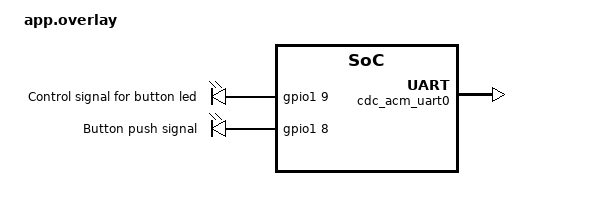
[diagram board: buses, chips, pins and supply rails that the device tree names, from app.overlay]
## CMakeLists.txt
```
#
# Copyright (c) 2024 Nordic Semiconductor
#
# SPDX-License-Identifier: LicenseRef-Nordic-5-Clause
#

cmake_minimum_required(VERSION 3.20.0)
find_package(Zephyr REQUIRED HINTS $ENV{ZEPHYR_BASE})
project(iso_time_sync)

target_include_directories(app PRIVATE include)
target_sources(app PRIVATE src/main.c src/timed_led_toggle.c src/uart_console.c src/buzzer.c src/buzzer_control.c src/param_stack.c)

if (CONFIG_BT_CENTRAL)
    target_sources(app PRIVATE src/central.c)
endif()

if (CONFIG_BT_PERIPHERAL)
    target_sources(app PRIVATE src/peripheral.c)
endif()

if (CONFIG_SOC_COMPATIBLE_NRF52X)
    target_sources(app PRIVATE src/controller_time_nrf52.c)
elseif (CONFIG_SOC_COMPATIBLE_NRF5340_CPUAPP)
    target_sources(app PRIVATE src/controller_time_nrf53_app.c)
elseif (CONFIG_SOC_SERIES_NRF54LX)
    target_sources(app PRIVATE src/controller_time_nrf54l.c)
else()
    MESSAGE(FATAL_ERROR "Unsupported series")
endif()
```

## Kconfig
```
source "Kconfig.zephyr"

config BUZZER_ROLE_MODE_CONTROLLER
	bool "Act as the buzzer controller"
```

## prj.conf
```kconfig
#
# Copyright (c) 2024 Nordic Semiconductor
#
# SPDX-License-Identifier: LicenseRef-Nordic-5-Clause
#

CONFIG_NCS_SAMPLES_DEFAULTS=y

CONFIG_BT_DEVICE_NAME="Buzzer"
CONFIG_BT=y
CONFIG_BT_PERIPHERAL=y
CONFIG_BT_CENTRAL=y
CONFIG_BT_MAX_CONN=5
CONFIG_BT_CTLR_SDC_PERIPHERAL_COUNT=1
CONFIG_BT_CTLR_TX_PWR_PLUS_8=y

CONFIG_BT_CONN_TX_MAX=250
CONFIG_BT_L2CAP_TX_BUF_COUNT=250
CONFIG_BT_BUF_ACL_TX_COUNT=250

CONFIG_BT_GATT_CLIENT=y

CONFIG_CONSOLE=y
CONFIG_CONSOLE_SUBSYS=y
CONFIG_CONSOLE_HANDLER=y
CONFIG_CONSOLE_GETCHAR=y
CONFIG_UART_INTERRUPT_DRIVEN=y

CONFIG_BT_CTLR_SDC_CONN_ANCHOR_POINT_REPORT=y
CONFIG_BT_HCI_VS_EVT_USER=y

CONFIG_BUILD_OUTPUT_UF2=y
CONFIG_ROM_START_OFFSET=0x1000

CONFIG_USB_DEVICE_STACK=y
CONFIG_USB_DEVICE_PRODUCT="Zephyr CDC ACM sample"
CONFIG_USB_DEVICE_PID=0x0001

CONFIG_BUZZER_ROLE_MODE_CONTROLLER=y
```

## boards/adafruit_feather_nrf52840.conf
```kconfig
#
# Copyright (c) 2024 Nordic Semiconductor
#
# SPDX-License-Identifier: LicenseRef-Nordic-5-Clause
#

CONFIG_NRFX_TIMER1=y
CONFIG_NRFX_RTC2=y
CONFIG_NRFX_GPPI=y
CONFIG_NRFX_EGU0=y
```

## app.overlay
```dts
/*
 * Copyright (c) 2021 Nordic Semiconductor ASA
 *
 * SPDX-License-Identifier: Apache-2.0
 */
&zephyr_udc0 {
    cdc_acm_uart0: cdc_acm_uart0 {
    	compatible = "zephyr,cdc-acm-uart";
        label = "CDC_ACM_0";
    };
};

/ {
    leds {
        led_drive: led_drive0 {
            gpios = <&gpio1 9 0>;
            label = "Control signal for button led";
        };
        push_button: push_button0 {
            gpios = <&gpio1 8 0>;
            label = "Button push signal";
        };   
    };
};
```

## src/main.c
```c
/*
 * Copyright (c) 2024 Nordic Semiconductor ASA
 *
 * SPDX-License-Identifier: LicenseRef-Nordic-5-Clause
 */

#include <zephyr/kernel.h>
#include <zephyr/console/console.h>
#include "conn_time_sync.h"
#include <zephyr/usb/usb_device.h>
#include <zephyr/drivers/uart.h>
#include "uart_console.h"

int main(void)
{
	console_init();
	
#ifdef CONFIG_BUZZER_ROLE_MODE_CONTROLLER
	uart_console_printf("Configured as buzzer controller\n");
	central_start();
#else
	uart_console_printf("Configured as buzzer\n");
	peripheral_start();
#endif
}
```

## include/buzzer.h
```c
#ifndef BUZZER_H
#define BUZZER_H
#include <stdint.h>
#include <zephyr/bluetooth/gatt.h>

ssize_t buzzer_arm_recieved(struct bt_conn *conn,
    const struct bt_gatt_attr *attr,
    const void *buf, uint16_t len,
    uint16_t offset, uint8_t flags);
ssize_t buzzer_light_recieved(struct bt_conn *conn,
        const struct bt_gatt_attr *attr,
        const void *buf, uint16_t len,
        uint16_t offset, uint8_t flags);
void buzzer_device_init(void);
void pressed_ccc_cfg_changed(const struct bt_gatt_attr *attr,
	uint16_t value);
void buzzer_device_reset(void);
void buzzer_update_offset(uint64_t central_timestamp, uint64_t peripheral_timestamp);
void buzzer_set_arm_flag(void);

#endif // BUZZER_H
```

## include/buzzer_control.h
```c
#ifndef BUZZER_CONTROL_H
#define BUZZER_CONTROL_H
#include <stdint.h>
#include <zephyr/bluetooth/conn.h>

void buzzer_controller_init(void);
int get_buzzer_chars(struct bt_conn *conn, uint16_t *timed_handle);

void controller_arm(void);
void controller_reset(void);

#endif // BUZZER_CONTROL_H
```

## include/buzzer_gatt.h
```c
#ifndef BUZZER_GATT_H
#define BUZZER_GATT_H

#include <zephyr/bluetooth/gatt.h>

// Define the Buzzer service
#define BT_UUID_BUZZER_SERVICE_VAL \
	BT_UUID_128_ENCODE(0xB0B10002, 0x7009, 0x4BEE, 0xA6F8, 0xE1DC3FF02B92)
#define BT_UUID_BUZZER_SERVICE \
	BT_UUID_DECLARE_128(BT_UUID_BUZZER_SERVICE_VAL)

// Buzzer ARM Characteristic
#define BT_UUID_BUZZER_ARM_CHAR_VAL \
	BT_UUID_128_ENCODE(0xB0B10003, 0x7009, 0x4BEE, 0xA6F8, 0xE1DC3FF02B92)
#define BT_UUID_BUZZER_ARM_CHAR \
	BT_UUID_DECLARE_128(BT_UUID_BUZZER_ARM_CHAR_VAL)	

// Buzzer Pressed Characteristic
#define BT_UUID_BUZZER_PRESSED_CHAR_VAL \
	BT_UUID_128_ENCODE(0xB0B10004, 0x7009, 0x4BEE, 0xA6F8, 0xE1DC3FF02B92)
#define BT_UUID_BUZZER_PRESSED_CHAR \
	BT_UUID_DECLARE_128(BT_UUID_BUZZER_PRESSED_CHAR_VAL)	

// Buzzer Light Characteristic
#define BT_UUID_BUZZER_LIGHT_CHAR_VAL \
	BT_UUID_128_ENCODE(0xB0B10005, 0x7009, 0x4BEE, 0xA6F8, 0xE1DC3FF02B92)
#define BT_UUID_BUZZER_LIGHT_CHAR \
	BT_UUID_DECLARE_128(BT_UUID_BUZZER_LIGHT_CHAR_VAL)	

#endif // BUZZER_GATT_H
```

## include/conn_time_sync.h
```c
/*
 * Copyright (c) 2024 Nordic Semiconductor ASA
 *
 * SPDX-License-Identifier: LicenseRef-Nordic-5-Clause
 */

#ifndef CONN_TIME_SYNC_H__
#define CONN_TIME_SYNC_H__

/**
 * @file
 * @defgroup conn_time_sync Definitions for the connection time sync sample.
 * @{
 * @brief Definitions for the connection time sync sample.
 *
 * This file contains common definitions and API declarations
 * used by the sample.
 */

#include <stdint.h>
#include <stdbool.h>
#include <zephyr/kernel.h>

/** @brief  Timed action service UUID */
#define BT_UUID_TIMED_ACTION_SERVICE_VAL \
	BT_UUID_128_ENCODE(0xA88278D0, 0x7009, 0x4BEE, 0xA6F8, 0xE1DC3FF02B92)
#define BT_UUID_TIMED_ACTION_SERVICE \
	BT_UUID_DECLARE_128(BT_UUID_TIMED_ACTION_SERVICE_VAL)

/** @brief Timed action characteristic UUID */
#define BT_UUID_TIMED_ACTION_CHAR_VAL \
	BT_UUID_128_ENCODE(0xA88278D1, 0x7009, 0x4BEE, 0xA6F8, 0xE1DC3FF02B92)
#define BT_UUID_TIMED_ACTION_CHAR \
	BT_UUID_DECLARE_128(BT_UUID_TIMED_ACTION_CHAR_VAL)

/** @brief Start central demo. */
void central_start(void);

/** @brief Start peripheral demo. */
void peripheral_start(void);

/** @brief The timed action message
 *
 * The timed action message represents the information
 * sent from the central to the peripheral to allow time synchronization.
 * The anchor point information is the common time reference between
 * the central and peripheral.
 *
 * This samples transmits the anchor point time and trigger time
 * in a single packet. Other applications may consider sending those
 * separately.
 */
struct timed_action {
	uint64_t anchor_point_us_central_clock;
	uint16_t anchor_point_event_counter;
} __packed;

// static inline void timed_action_print(struct timed_action *action)
// {
// 	uart_printf("c_anchor point (time=%llu, counter=%u), c_trigger_time %llu, value %d\n",
// 		action->anchor_point_us_central_clock,
// 		action->anchor_point_event_counter,
// 		action->trigger_time_us_central_clock,
// 		action->led_value);
// }

/** @brief Obtain the current Bluetooth controller time.
 *
 * The timestamps are based upon this clock.
 *
 * @return The current controller time.
 */
uint64_t controller_time_us_get(void);

/** @brief Set the controller to trigger a PPI event at the given timestamp.
 *
 * @param timestamp_us The timestamp where it will trigger.
 */
void controller_time_trigger_set(uint64_t timestamp_us);

/** @brief Get the address of the event that will trigger.
 *
 * @return The address of the event that will trigger.
 */
uint32_t controller_time_trigger_event_addr_get(void);

/** @brief Initialize the module handling timed toggling of an LED.
 *
 * @return 0 on success, failure otherwise.
 */
int timed_led_toggle_init(void);

/** @brief Toggle the LED using the given value at the given timestamp.
 *
 * @param value The LED value.
 * @param timestamp_us The time when the LED will be set, in microseconds.
 *                     The time is specified in controller clock units.
 */
void timed_led_toggle_trigger_at(uint8_t value, uint32_t timestamp_us);

#endif

/**
 * @}
 */
```

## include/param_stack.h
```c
#ifndef PARAM_STACK_H
#define PARAM_STACK_H
#include <zephyr/bluetooth/gatt.h>
int param_stack_get_write(struct bt_gatt_write_params **data);
int param_stack_get_read(struct bt_gatt_read_params **data);
int param_stack_free_write(struct bt_gatt_write_params *data);
int param_stack_free_read(struct bt_gatt_read_params *data);
#endif
```

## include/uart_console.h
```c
#ifndef UART_CONSOLE_H__
#define UART_CONSOLE_H__
void uart_console_printf(char *fmt, ...);
void uart_console_command_loop(void);
#endif
```

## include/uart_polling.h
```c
#ifndef UART_POLLING_H__
#define UART_POLLING_H__
int uart_poll_init(void);
void uart_poll_print(char *message);
void uart_printf(char *fmt, ...);
int uart_get_char(char *character);
#endif
```

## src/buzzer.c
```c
#include <zephyr/kernel.h>
#include <zephyr/bluetooth/gatt.h>
#include <zephyr/sys/atomic.h>
#include <zephyr/drivers/gpio.h>
#include "uart_console.h"
#include "conn_time_sync.h"
#include "param_stack.h"
#include "buzzer_gatt.h"

#define BUZZER_LOCKOUT 2000
#define BUZZER_LED_FLASH_DELAY_MS 200

// Data structure definitions
// Buzzer state struct
struct buzzer_params {
	uint64_t buzzer_pushed_timestamp; 
	uint64_t armed_timestamp;
	atomic_t lock;
	atomic_t armed;
	uint8_t lights;
};

struct buzzer_sync {
    int64_t offset_to_central;
    atomic_t offset_valid;
};

// Consts
static const struct gpio_dt_spec input_button = GPIO_DT_SPEC_GET(DT_NODELABEL(push_button), gpios);
static const struct gpio_dt_spec led_drive = GPIO_DT_SPEC_GET(DT_NODELABEL(led_drive), gpios);

// Function Declarations
void buzzer_led_init(void);
void buzzer_led_on(void);
void buzzer_led_off(void);
void buzzer_led_start_flash(void);

// Callback data for gpio
static struct gpio_callback pin_cb_data;

// Device state
static struct buzzer_params buzzer_state;
static atomic_t indicate_flag;
static struct bt_gatt_indicate_params ind_params;
static struct buzzer_sync buzzer_timing;
static int led_state = 0;

// Function Declarations
static void on_indicate_buzzer_time(struct k_work *work);

void buzzer_update_offset(uint64_t central_timestamp, uint64_t peripheral_timestamp)
{
    buzzer_timing.offset_to_central = central_timestamp - peripheral_timestamp;
    atomic_set_bit(&buzzer_timing.offset_valid, 0);
}

static void on_reenable_buzzer(struct k_work *work)
{
	gpio_pin_interrupt_configure_dt(&input_button, GPIO_INT_EDGE_TO_ACTIVE);
}
K_WORK_DELAYABLE_DEFINE(buzzer_reenable, on_reenable_buzzer);


K_WORK_DEFINE(indicate_buzzer_time, on_indicate_buzzer_time);

// Buzzer button ISR
static void pin_isr_buzzer(const struct device *dev, struct gpio_callback *cb, uint32_t pins)
{
	// Check if buzzer is not armed
	if(!atomic_test_bit(&buzzer_state.armed, 0)){
		// Disable buzzer for BUZZER_LOCKOUT
		uart_console_printf("Buzzer Locked\n");
		gpio_pin_interrupt_configure_dt(&input_button, GPIO_INT_DISABLE);
		k_work_schedule(&buzzer_reenable, K_MSEC(BUZZER_LOCKOUT));
	}
	// Buzzer is armed, check if we already have a valid buzz time and valid offset
	else if(!buzzer_state.buzzer_pushed_timestamp && atomic_test_bit(&buzzer_timing.offset_valid, 0)){
		// Set the buzzer time
		buzzer_state.buzzer_pushed_timestamp = controller_time_us_get() + buzzer_timing.offset_to_central;
		uart_console_printf("Buzzed in @ %llu central\n", buzzer_state.buzzer_pushed_timestamp);
		k_work_submit(&indicate_buzzer_time);
	}
}


static void gpio_input_config(void)
{
	gpio_pin_configure_dt(&input_button, GPIO_INPUT | GPIO_PULL_UP);
	gpio_pin_interrupt_configure_dt(&input_button, GPIO_INT_EDGE_TO_ACTIVE);
	gpio_init_callback(&pin_cb_data, pin_isr_buzzer, BIT(input_button.pin));
	gpio_add_callback(input_button.port, &pin_cb_data);
}

void buzzer_device_init(void)
{
    gpio_input_config();
	buzzer_led_init();
}

void buzzer_device_reset(void)
{
    buzzer_state.buzzer_pushed_timestamp = 0;
    buzzer_state.armed_timestamp = 0;
    buzzer_state.lights = 0;
    atomic_clear_bit(&buzzer_state.armed, 0);
    atomic_clear_bit(&buzzer_state.lock, 0);
    atomic_clear_bit(&indicate_flag, 0);

    buzzer_timing.offset_to_central = 0;
    atomic_clear_bit(&buzzer_timing.offset_valid, 0);

	buzzer_led_off();
}


void pressed_ccc_cfg_changed(const struct bt_gatt_attr *attr,
	uint16_t value)
{
	if(value == BT_GATT_CCC_INDICATE){
		atomic_set_bit(&indicate_flag, 0);
		uart_console_printf("Client Subscribed\n");
	}else{
		atomic_clear_bit(&indicate_flag, 0);
		uart_console_printf("Client Unsubscribed\n");
	}
}


static void on_indicate_buzzer_time(struct k_work *work)
{
	// Check to see if we are still armed and indications are enabled
	if(atomic_test_bit(&buzzer_state.armed, 0) && atomic_test_bit(&indicate_flag, 0)){
		uart_console_printf("Indicate\n");
		ind_params.uuid = BT_UUID_BUZZER_PRESSED_CHAR;
		ind_params.func = NULL;
		ind_params.destroy = NULL;
		ind_params.data = &buzzer_state.buzzer_pushed_timestamp ;
		ind_params.len = sizeof(buzzer_state.buzzer_pushed_timestamp );
		bt_gatt_indicate(NULL, &ind_params);
	}
}
// Callback for the buzzer arming
ssize_t buzzer_arm_recieved(struct bt_conn *conn,
    const struct bt_gatt_attr *attr,
    const void *buf, uint16_t len,
    uint16_t offset, uint8_t flags)
{
    if (len != sizeof(buzzer_state.armed_timestamp) || offset != 0) {
        return BT_GATT_ERR(BT_ATT_ERR_INVALID_ATTRIBUTE_LEN);
    }

    // Obtain a lock for the buzzer struct
    if(atomic_test_and_set_bit(&buzzer_state.lock, 0)){
    uart_console_printf("ERROR ARM: Already Locked\n");
        return 0;
    }
    memcpy(&buzzer_state.armed_timestamp, buf, sizeof(buzzer_state.armed_timestamp));

    // Set the ARM flag
    if(buzzer_state.armed_timestamp){
        uart_console_printf("Arm buzzer @ %llu central\n", buzzer_state.armed_timestamp);
        // Set the buzzer time trigger
        timed_led_toggle_trigger_at(led_state, buzzer_state.armed_timestamp - buzzer_timing.offset_to_central);
		if(led_state){
			led_state = 0;
		}else{
			led_state = 1;
		}
    }else{
        atomic_clear_bit(&buzzer_state.armed, 0);
        buzzer_state.buzzer_pushed_timestamp = 0;
		buzzer_led_off();
        uart_console_printf("Buzzer Disarmed\n");
    }

    atomic_clear_bit(&buzzer_state.lock, 0);
    return len;
}

ssize_t buzzer_light_recieved(struct bt_conn *conn,
    const struct bt_gatt_attr *attr,
    const void *buf, uint16_t len,
    uint16_t offset, uint8_t flags)
{
    if (len != sizeof(buzzer_state.lights) || offset != 0) {
        return BT_GATT_ERR(BT_ATT_ERR_INVALID_ATTRIBUTE_LEN);
    }

    // Obtain a lock for the buzzer struct
    if(atomic_test_and_set_bit(&buzzer_state.lock, 0)){
    uart_console_printf("ERROR ARM: Already Locked\n");
        return 0;
    }
    memcpy(&buzzer_state.lights, buf, sizeof(buzzer_state.lights));

    // Set the ARM flag
	if(buzzer_state.lights){
		buzzer_led_on();
	}else{
		buzzer_led_off();
	}

    atomic_clear_bit(&buzzer_state.lock, 0);
    return len;
}

// Function used by the timer isr to set the arming flag
void buzzer_set_arm_flag(void)
{
    atomic_set_bit(&buzzer_state.armed, 0);
	buzzer_led_start_flash();
    uart_console_printf("Buzzer ARMED\n");
}

///////////////////////////////////////////////////////
// Buzzer LED Functions
///////////////////////////////////////////////////////

void buzzer_led_init(void)
{
    gpio_pin_configure_dt(&led_drive, GPIO_OUTPUT_ACTIVE);
	buzzer_led_off();
}

void buzzer_led_on(void)
{
    gpio_pin_set_dt(&led_drive, 1);
}

void buzzer_led_off(void)
{
    gpio_pin_set_dt(&led_drive, 0);
}

static void on_buzzer_led_flash(struct k_work *work)
{
	// Make sure buzzer is still armed
	if(atomic_test_bit(&buzzer_state.armed, 0)){
		gpio_pin_toggle_dt(&led_drive);
		k_work_schedule(k_work_delayable_from_work(work), K_MSEC(BUZZER_LED_FLASH_DELAY_MS));
	}
}
K_WORK_DELAYABLE_DEFINE(buzzer_led_flash, on_buzzer_led_flash);

void buzzer_led_start_flash(void)
{
    buzzer_led_on();
    k_work_schedule(&buzzer_led_flash, K_MSEC(BUZZER_LED_FLASH_DELAY_MS));
}
```

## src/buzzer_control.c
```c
#include <zephyr/bluetooth/gatt.h>
#include <zephyr/sys/atomic.h>
#include <zephyr/drivers/gpio.h>
#include "param_stack.h"
#include "buzzer_control.h"
#include "uart_console.h"
#include "buzzer_gatt.h"
#include "conn_time_sync.h"

#define BUZZER_ARM_DELAY_US 120000

// Time to wait for buzzes before deciding the winner in ms
#define BUZZER_DECIDE_WINNER_DELAY 200

// Data structure definitions
struct controller_params {
	uint64_t arm_timestamp;
    atomic_t recievced_first_buzz;
	atomic_t lock;
};

struct disabled_buzzers {
	bt_addr_t buzzer_addr[CONFIG_BT_MAX_CONN];
	int num_buzzers;
};

struct device_params {
	uint64_t last_buzz_time;
	atomic_t last_buzz_time_valid;
	uint8_t light_on;
	const bt_addr_le_t *buzzer_addr;
	uint16_t buzzer_char_handle;
 	uint16_t pressed_char_handle;
	uint16_t light_char_handle;
 	uint16_t *timed_char_handle_ptr;
};

struct device_ids {
	const bt_addr_t buzzer_addr;
	const char buzzer_name[25];
};

// Consts
static const struct gpio_dt_spec input_button = GPIO_DT_SPEC_GET(DT_NODELABEL(button0), gpios);
static const struct bt_uuid *gatt_ccc_uuid = BT_UUID_GATT_CCC;

// Buzzer IDs
const struct device_ids buzzer_ids[] = {
	{
		.buzzer_addr = {{0xEE, 0xA1, 0x46, 0x6F, 0x1B, 0xCA}},
		.buzzer_name = "Green"
	},
	{
		.buzzer_addr = {{0x6B, 0x65, 0xF0, 0x32, 0xB1, 0xD7}},
		.buzzer_name = "Red"
	},
	{
		.buzzer_addr = {{0x4D, 0x2E, 0x9C, 0x2F, 0xE3, 0xD9}},
		.buzzer_name = "Yellow"
	},
	{
		.buzzer_addr = {{0xD2, 0xB4, 0xB2, 0xFE, 0x6F, 0xDF}},
		.buzzer_name = "Blue"
	}
};

// State Variables
struct controller_params controller_state;
static struct bt_gatt_subscribe_params subscribe_params;
static struct bt_gatt_discover_params char_params;
static struct bt_gatt_discover_params ccc_params;
static struct device_params device_state[CONFIG_BT_MAX_CONN];
static struct disabled_buzzers disabled_buzzers;

// Callback data for gpio
static struct gpio_callback pin_cb_data;

// Function declarations
static void gpio_input_config(void);
static void send_arm_packet(struct bt_conn *conn, void *data);
static void send_light_packet(struct bt_conn *conn, int light_setting);

static void on_send_buzzer_arm(struct k_work *work)
{
	printk("Send ARM\n");

	controller_state.arm_timestamp = controller_time_us_get() + BUZZER_ARM_DELAY_US;
	bt_conn_foreach(BT_CONN_TYPE_LE, send_arm_packet, &controller_state.arm_timestamp);
}
K_WORK_DEFINE(send_arm_signal, on_send_buzzer_arm);

// Initialize the buzzer controller
void buzzer_controller_init(void)
{
	gpio_input_config();
    // Clear state
    controller_state.arm_timestamp = 0;
    atomic_clear_bit(&controller_state.lock, 0);
    atomic_clear_bit(&controller_state.recievced_first_buzz, 0);
	disabled_buzzers.num_buzzers = 0;
}

static void controller_arm_button_isr(const struct device *dev, struct gpio_callback *cb, uint32_t pins)
{
    // Queue the arm signal packet
	k_work_submit(&send_arm_signal);
}

// Function that should be called for every buzzer disarm
static void controller_disarm_buzzers(void)
{
    // Disarm buzzers
    controller_state.arm_timestamp = 0;
    atomic_clear_bit(&controller_state.recievced_first_buzz, 0);
	bt_conn_foreach(BT_CONN_TYPE_LE, send_arm_packet, &controller_state.arm_timestamp);	
}

// External functions
void controller_arm(void)
{
	k_work_submit(&send_arm_signal);
}

void controller_reset(void)
{
	disabled_buzzers.num_buzzers = 0;
	controller_disarm_buzzers();
}

// Configure the input button
static void gpio_input_config(void)
{
	gpio_pin_configure_dt(&input_button, GPIO_INPUT);
	gpio_pin_interrupt_configure_dt(&input_button, GPIO_INT_EDGE_TO_ACTIVE);

    gpio_init_callback(&pin_cb_data, controller_arm_button_isr, BIT(input_button.pin));

	gpio_add_callback(input_button.port, &pin_cb_data);
}

// Callback for when a write packet is sent
static void write_cb(struct bt_conn *conn, uint8_t err, struct bt_gatt_write_params *params)
{
    if (err) {
        printk("GATT Write failed: %d\n", err);
    } else {
        printk("GATT Write successful\n");
    } 
	param_stack_free_write(params);
}

static void send_arm_packet(struct bt_conn *conn, void *data)
{
	int err;
	struct bt_conn_info conn_info;

	err = bt_conn_get_info(conn, &conn_info);
	if (err) {
		return;
	}

	uint8_t conn_index = bt_conn_index(conn);

	if (conn_info.state != BT_CONN_STATE_CONNECTED) {
		return;
	}

	if (device_state[conn_index].buzzer_char_handle == 0) {
		/* Service discovery not yet complete. */
		return;
	}

	// Get connection address
	const bt_addr_le_t *buzzer_addr = bt_conn_get_dst(conn);
	// Null Check
	if(!buzzer_addr){
		printk("NULL connection pointer\n");
		return;
	}
	// Clear the light of the last disabled buzzer if any
	if(disabled_buzzers.num_buzzers){
		int last_disabled_idx = disabled_buzzers.num_buzzers - 1; 
		if(bt_addr_cmp(&disabled_buzzers.buzzer_addr[last_disabled_idx], &buzzer_addr->a) == 0){
			send_light_packet(conn, 0);
		}	
	}
	// Don't send the arming signal if the buzzer has been disabled
	int i;
	for(i = 0; i < disabled_buzzers.num_buzzers; i++){
		if(bt_addr_cmp(&disabled_buzzers.buzzer_addr[i], &buzzer_addr->a) == 0){
			return;
		}
	}
	struct bt_gatt_write_params *write_ptr;
	if(param_stack_get_write(&write_ptr)){
		uart_console_printf("Error getting write buffer\n");
		return;
	}
	// Clear last buzz time before sending arm packet
	atomic_clear_bit(&device_state[conn_index].last_buzz_time_valid, 0);
	write_ptr->handle = device_state[conn_index].buzzer_char_handle;
	write_ptr->data = data;
	write_ptr->length = sizeof(uint64_t);
	write_ptr->func = write_cb;

	bt_gatt_write(conn, write_ptr);
}

static const char *get_buzzer_name(const bt_addr_t *addr)
{
	int i;
	for(i = 0; i < sizeof(buzzer_ids)/sizeof(buzzer_ids[0]); i++){
		if(bt_addr_cmp(addr, &buzzer_ids[i].buzzer_addr) == 0){
			return buzzer_ids[i].buzzer_name;
		}
	}
	return "Unknown";
}

static void send_light_packet(struct bt_conn *conn, int light_setting)
{
	int err;
	struct bt_conn_info conn_info;

	err = bt_conn_get_info(conn, &conn_info);
	if (err) {
		return;
	}

	uint8_t conn_index = bt_conn_index(conn);

	if (conn_info.state != BT_CONN_STATE_CONNECTED) {
		return;
	}

	if (device_state[conn_index].light_char_handle == 0) {
		/* Service discovery not yet complete. */
		return;
	}

	struct bt_gatt_write_params *write_ptr;
	if(param_stack_get_write(&write_ptr)){
		uart_console_printf("Error getting write buffer\n");
		return;
	}

	if(light_setting){
		device_state[conn_index].light_on = 1;
	}else{
		device_state[conn_index].light_on = 0;
	}

	write_ptr->handle = device_state[conn_index].light_char_handle;
	write_ptr->data = &device_state[conn_index].light_on;
	write_ptr->length = sizeof(uint8_t);
	write_ptr->func = write_cb;

	bt_gatt_write(conn, write_ptr);
}

static void on_decide_winner(struct k_work *work)
{
    // Get all recieved buzzer times and compare (find the lowest value)
    uart_console_printf("Deciding winner\n");	

	int i;
	uint64_t lowest_time = UINT64_MAX;
	uint8_t lowest_index = 0;
	for(i = 0; i < CONFIG_BT_MAX_CONN; i++){
		if(atomic_test_bit(&device_state[i].last_buzz_time_valid, 0)){
			if(device_state[i].last_buzz_time < lowest_time){
				lowest_time = device_state[i].last_buzz_time;
				lowest_index = i;
			}
		}
	}

    // Disarm buzzers
	controller_disarm_buzzers();

	uart_console_printf("Winner: %s\n", get_buzzer_name(&device_state[lowest_index].buzzer_addr->a));

	// Add the winning buzzer to the disabled list for if the next buzzer command is issued
	bt_addr_copy(&disabled_buzzers.buzzer_addr[disabled_buzzers.num_buzzers], &device_state[lowest_index].buzzer_addr->a);
	disabled_buzzers.num_buzzers += 1;

	// Turn on the light for the winner
	struct bt_conn *conn = bt_conn_lookup_addr_le(BT_ID_DEFAULT, device_state[lowest_index].buzzer_addr);
	send_light_packet(conn, 1);
	bt_conn_unref(conn);
    return;
}
K_WORK_DELAYABLE_DEFINE(decide_winner, on_decide_winner);

// Callback for when a indication packet is recieved
static uint8_t indicate_callback(struct bt_conn *conn, struct bt_gatt_subscribe_params *params, const void *data, uint16_t length){
	uint8_t conn_index = bt_conn_index(conn);

	if(conn == NULL){
		uart_console_printf("Device is being unpaired\n");\
		return BT_GATT_ITER_STOP;
	}
	if(data == NULL){
		uart_console_printf("Subscription was removed\n");
		return BT_GATT_ITER_STOP;
	}

	if (length != sizeof(device_state[conn_index].last_buzz_time)) {
		uart_console_printf("Error: ARM Timestamp\n");
		return BT_GATT_ITER_CONTINUE;
	}

	// Ignore if controller has transitioned to disarmed state
	if(controller_state.arm_timestamp == 0){
		return BT_GATT_ITER_CONTINUE;	
	}

    // Data is a valid buzz
    // Check if this is the first buzzer to buzz in
    if(!atomic_test_bit(&controller_state.recievced_first_buzz, 0)){
        atomic_set_bit(&controller_state.recievced_first_buzz, 0);
        uart_console_printf("First buzz\n");
        k_work_schedule(&decide_winner, K_MSEC(BUZZER_DECIDE_WINNER_DELAY));
    }
	
	memcpy(&device_state[conn_index].last_buzz_time, data, sizeof(device_state[conn_index].last_buzz_time));
	atomic_set_bit(&device_state[conn_index].last_buzz_time_valid, 0);
	
	const bt_addr_le_t *buzzer_addr = bt_conn_get_dst(conn);
	uart_console_printf("%s buzzed in @ %llu\n", get_buzzer_name(&buzzer_addr->a), device_state[conn_index].last_buzz_time);

	return BT_GATT_ITER_CONTINUE;
}

static int buzzer_subscribe(struct bt_conn *conn)
{
	uint8_t conn_index = bt_conn_index(conn);
	subscribe_params.notify = indicate_callback;
	subscribe_params.value = BT_GATT_CCC_INDICATE;
	subscribe_params.value_handle = device_state[conn_index].pressed_char_handle;
	// subscribe_params.ccc_handle set by discovery
	return bt_gatt_subscribe(conn, &subscribe_params);
}

static uint8_t on_discover_ccc(struct bt_conn *conn,
	const struct bt_gatt_attr *attr,
	struct bt_gatt_discover_params *params)
{
	if (attr) {
		// uart_console_printf("Found Pressed CCC\n");
		subscribe_params.ccc_handle = attr->handle;

		buzzer_subscribe(conn);

		return BT_GATT_ITER_STOP;
	} else {
		uart_console_printf("CCC Done\n");
		return BT_GATT_ITER_STOP;
	}
	return BT_GATT_ITER_STOP;
}

static uint8_t on_discover_char(struct bt_conn *conn,
	const struct bt_gatt_attr *attr,
	struct bt_gatt_discover_params *params)
{
	uint8_t conn_index = bt_conn_index(conn);
	if (attr) {
		struct bt_gatt_chrc *char_val = attr->user_data;
		if(bt_uuid_cmp(char_val->uuid, BT_UUID_BUZZER_ARM_CHAR) == 0){
			// uart_console_printf("Found Arm Characteristic\n");
			device_state[conn_index].buzzer_char_handle = bt_gatt_attr_value_handle(attr);
		}
		else if(bt_uuid_cmp(char_val->uuid, BT_UUID_TIMED_ACTION_CHAR) == 0){
			// uart_console_printf("Found Time Characteristic\n");
			*device_state[conn_index].timed_char_handle_ptr = bt_gatt_attr_value_handle(attr);
		}
		else if(bt_uuid_cmp(char_val->uuid, BT_UUID_BUZZER_PRESSED_CHAR) == 0){
			// uart_console_printf("Found Pressed Characteristic\n");
			device_state[conn_index].pressed_char_handle = bt_gatt_attr_value_handle(attr);
			ccc_params.uuid = gatt_ccc_uuid;
			ccc_params.start_handle = attr->handle + 2;
			ccc_params.end_handle = BT_ATT_LAST_ATTRIBUTE_HANDLE;
			ccc_params.type = BT_GATT_DISCOVER_DESCRIPTOR;
			ccc_params.func = on_discover_ccc;
			bt_gatt_discover(conn, &ccc_params);
		}
		else if(bt_uuid_cmp(char_val->uuid, BT_UUID_BUZZER_LIGHT_CHAR) == 0){
			// uart_console_printf("Found Light Characteristic\n");
			device_state[conn_index].light_char_handle = bt_gatt_attr_value_handle(attr);
		}
		return BT_GATT_ITER_CONTINUE;
	} else {
		uart_console_printf("Discovery Done\n");
		return BT_GATT_ITER_STOP;
	}
	return BT_GATT_ITER_STOP;
}

int get_buzzer_chars(struct bt_conn *conn, uint16_t *timed_handle)
{
	char_params.uuid = NULL;
	char_params.func = on_discover_char;
	char_params.start_handle = BT_ATT_FIRST_ATTRIBUTE_HANDLE;
	char_params.end_handle = BT_ATT_LAST_ATTRIBUTE_HANDLE;
	char_params.type = BT_GATT_DISCOVER_CHARACTERISTIC;

	uint8_t conn_index = bt_conn_index(conn);
	device_state[conn_index].timed_char_handle_ptr = timed_handle;

	// Set address
	device_state[conn_index].buzzer_addr = bt_conn_get_dst(conn);

	// if(bt_addr_cmp(&device_state[conn_index].buzzer_addr->a, &buzzer_ids[0].buzzer_addr) == 0){
	// 	uart_console_printf("Found buzzer: %s\n", buzzer_ids[0].buzzer_name);
	// }

	return bt_gatt_discover(conn, &char_params);
}
```

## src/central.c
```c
/*
 * Copyright (c) 2024 Nordic Semiconductor ASA
 *
 * SPDX-License-Identifier: LicenseRef-Nordic-5-Clause
 */

#include <zephyr/sys/atomic.h>
#include <zephyr/bluetooth/bluetooth.h>
#include <zephyr/bluetooth/conn.h>
#include <zephyr/bluetooth/hci.h>
#include <bluetooth/services/nus.h>
#include "conn_time_sync.h"
#include <bluetooth/hci_vs_sdc.h>
#include "uart_console.h"
#include "buzzer_control.h"

#define LED_TOGGLE_PERIOD_MS 500

#define LED_TOGGLE_TIME_OFFSET_US 50000

#define ADV_NAME_STR_MAX_LEN (sizeof(CONFIG_BT_DEVICE_NAME))

static void scan_start(void);

static bool led_value;
static uint8_t volatile conn_count;

static struct {
	atomic_t last_anchor_point_in_use;
	uint16_t timed_action_char_handle;
	uint16_t last_anchor_point_event_counter;
	uint64_t last_anchor_point_timestamp;
	struct timed_action timed_action_msg;
	struct bt_gatt_discover_params discovery_params;
} conn_state[CONFIG_BT_MAX_CONN];

struct bt_gatt_discover_params service_params;

static void send_timestamp_to_peripheral(struct bt_conn *conn, void *data)
{
	int err;
	struct bt_conn_info conn_info;

	err = bt_conn_get_info(conn, &conn_info);
	if (err) {
		return;
	}

	uint8_t conn_index = bt_conn_index(conn);

	if (conn_info.state != BT_CONN_STATE_CONNECTED) {
		return;
	}

	if (conn_state[conn_index].timed_action_char_handle == 0) {
		/* Service discovery not yet complete. */
		return;
	}

	if (atomic_test_and_set_bit(&conn_state[conn_index].last_anchor_point_in_use, 0)) {
		return;
	}

	conn_state[conn_index].timed_action_msg.anchor_point_us_central_clock =
		conn_state[conn_index].last_anchor_point_timestamp;
	conn_state[conn_index].timed_action_msg.anchor_point_event_counter =
		conn_state[conn_index].last_anchor_point_event_counter;

	atomic_clear_bit(&conn_state[conn_index].last_anchor_point_in_use, 0);

	err = bt_gatt_write_without_response(conn,
		conn_state[conn_index].timed_action_char_handle,
		&conn_state[conn_index].timed_action_msg,
		sizeof(struct timed_action),
		false);
	if (err) {
		printk("Failed writing to characteristic\n");
	} else {
		// printk("Sent to conn index %d: ", conn_index);
		// timed_action_print(&conn_state[conn_index].timed_action_msg);
	}
}

static void on_timestamp_send_timeout(struct k_work *work)
{
	uint64_t local_time_us = controller_time_us_get();
	uint64_t toggle_time_us = local_time_us + LED_TOGGLE_TIME_OFFSET_US;

	led_value = !led_value;

	// timed_led_toggle_trigger_at(led_value, toggle_time_us);

	bt_conn_foreach(BT_CONN_TYPE_LE, send_timestamp_to_peripheral, &toggle_time_us);

	k_work_schedule(k_work_delayable_from_work(work), K_MSEC(LED_TOGGLE_PERIOD_MS));
}

K_WORK_DELAYABLE_DEFINE(timestamp_send_work, on_timestamp_send_timeout);

static bool adv_data_parse_cb(struct bt_data *data, void *user_data)
{
	char *name = user_data;
	uint8_t len;

	switch (data->type) {
	case BT_DATA_NAME_SHORTENED:
	case BT_DATA_NAME_COMPLETE:
		len = MIN(data->data_len, ADV_NAME_STR_MAX_LEN - 1);
		memcpy(name, data->data, len);
		name[len] = '\0';
		return false;
	default:
		return true;
	}
}

static void device_found(const bt_addr_le_t *addr, int8_t rssi, uint8_t type,
			 struct net_buf_simple *ad)
{
	char name_str[ADV_NAME_STR_MAX_LEN] = {0};
	char addr_str[BT_ADDR_LE_STR_LEN];
	int err;

	/* We're only interested in connectable events */
	if (type != BT_GAP_ADV_TYPE_ADV_IND &&
	    type != BT_GAP_ADV_TYPE_ADV_DIRECT_IND) {
		return;
	}

	bt_data_parse(ad, adv_data_parse_cb, name_str);

	if (strncmp(name_str, CONFIG_BT_DEVICE_NAME, ADV_NAME_STR_MAX_LEN) != 0) {
		return;
	}

	bt_addr_le_to_str(addr, addr_str, sizeof(addr_str));
	uart_console_printf("Device found: %s (RSSI %d)\n", addr_str, rssi);

	if (bt_le_scan_stop()) {
		return;
	}

	struct bt_conn *unused_conn = NULL;

	err = bt_conn_le_create(addr, BT_CONN_LE_CREATE_CONN,
				BT_LE_CONN_PARAM(16, 16, 0, 200), &unused_conn);
	if (err) {
		printk("Create conn to %s failed (%d)\n", addr_str, err);
		scan_start();
	}

	if (unused_conn) {
		bt_conn_unref(unused_conn);
	}
}

static void scan_start(void)
{
	int err;

	err = bt_le_scan_start(BT_LE_SCAN_ACTIVE_CONTINUOUS, device_found);
	if (err) {
		printk("Scanning failed to start (err %d)\n", err);
		return;
	}

	printk("Scanning started\n");
}

// static uint8_t on_service_discover(struct bt_conn *conn,
// 	const struct bt_gatt_attr *attr,
// 	struct bt_gatt_discover_params *params)
// {
// 	if (attr) {
// 		uint8_t conn_index = bt_conn_index(conn);

// 		conn_state[conn_index].timed_action_char_handle =
// 			bt_gatt_attr_value_handle(attr);
// 		printk("Service discovery completed\n");
// 	} else {
// 		printk("Service discovery failed\n");
// 	}

// 	return BT_GATT_ITER_STOP;
// }

static void connected(struct bt_conn *conn, uint8_t err)
{
	char addr[BT_ADDR_LE_STR_LEN];

	bt_addr_le_to_str(bt_conn_get_dst(conn), addr, sizeof(addr));

	if (err) {
		printk("Failed to connect to %s 0x%02x %s\n", addr, err, bt_hci_err_to_str(err));

		scan_start();
		return;
	}

	printk("Connected: %s\n", addr);

	uint8_t conn_index = bt_conn_index(conn);

	// conn_state[conn_index].discovery_params.uuid = timed_char_uuid;
	// conn_state[conn_index].discovery_params.func = on_service_discover;
	// conn_state[conn_index].discovery_params.start_handle = BT_ATT_FIRST_ATTRIBUTE_HANDLE;
	// conn_state[conn_index].discovery_params.end_handle = BT_ATT_LAST_ATTRIBUTE_HANDLE;
	// conn_state[conn_index].discovery_params.type = BT_GATT_DISCOVER_CHARACTERISTIC;

	// // Go discover the gatt characteristics
	// err = bt_gatt_discover(conn, &conn_state[conn_index].discovery_params);
	// if (err) {
	// 	printk("Discovery failed, %d\n", err);
	// }

	err = get_buzzer_chars(conn, &conn_state[conn_index].timed_action_char_handle);
	if (err) {
		printk("Char Discovery failed, %d\n", err);
		bt_conn_disconnect(conn, BT_HCI_ERR_UNACCEPT_CONN_PARAM);
	}
	
	const uint8_t peripheral_conn_count = 1;

	conn_count++;
	if (conn_count < CONFIG_BT_MAX_CONN - peripheral_conn_count) {
		scan_start();
	}
}

static void disconnected(struct bt_conn *conn, uint8_t reason)
{
	char addr[BT_ADDR_LE_STR_LEN];

	bt_addr_le_to_str(bt_conn_get_dst(conn), addr, sizeof(addr));

	printk("Disconnected: %s, reason 0x%02x %s\n", addr, reason, bt_hci_err_to_str(reason));

	conn_count--;

	uint8_t conn_index = bt_conn_index(conn);

	/* Reset state */
	memset(&conn_state[conn_index], 0, sizeof(conn_state[0]));

	const uint8_t peripheral_conn_count = 1;

	if (conn_count == CONFIG_BT_MAX_CONN - peripheral_conn_count - 1) {
		scan_start();
	}
}

static bool on_conn_param_req(struct bt_conn *conn, struct bt_le_conn_param *param)
{
	ARG_UNUSED(conn);
	ARG_UNUSED(param);

	return false;
}

static struct bt_conn_cb conn_callbacks = {
	.connected = connected,
	.disconnected = disconnected,
	.le_param_req = on_conn_param_req,
};

static bool on_vs_evt(struct net_buf_simple *buf)
{
	uint8_t *subevent_code;
	struct bt_conn *conn;
	sdc_hci_subevent_vs_conn_anchor_point_update_report_t *evt = NULL;

	subevent_code = net_buf_simple_pull_mem(
		buf,
		sizeof(*subevent_code));

	switch (*subevent_code) {
	case SDC_HCI_SUBEVENT_VS_CONN_ANCHOR_POINT_UPDATE_REPORT:
		evt = (void *)buf->data;
		break;
	default:
		return false;
	}

	if (!evt) {
		return false;
	}

	// Get connection from the handle
	conn = bt_hci_conn_lookup_handle(evt->conn_handle);
	if (!conn) {
		return true;
	}

	// Get the current device index
	uint8_t conn_index = bt_conn_index(conn);

	// Release the connection
	bt_conn_unref(conn);
	conn = NULL;

	//uart_console_printf("%d\n", evt->event_counter);

	if (atomic_test_and_set_bit(&conn_state[conn_index].last_anchor_point_in_use, 0)) {
		return true;
	}

	conn_state[conn_index].last_anchor_point_timestamp = evt->anchor_point_us;
	conn_state[conn_index].last_anchor_point_event_counter = evt->event_counter;

	atomic_clear_bit(&conn_state[conn_index].last_anchor_point_in_use, 0);

	return true;
}

void central_start(void)
{
	int err;
	// Enable BLE
	err = bt_enable(NULL);
	if (err) {
		printk("Bluetooth init failed (err %d)\n", err);
		return;
	}

	// Initialize the buzzer controller system
	buzzer_controller_init();

	// Register user callback for HCI Vendor-Specific Events. 
	// In this case this is the anchor point
	// On the central device, this event is generated every connection interval. On the peripheral device, 
	// this event is only generated for connection events in which a packet from the central device is received.
	err = bt_hci_register_vnd_evt_cb(on_vs_evt);
	if (err) {
		printk("Failed to register HCI VS callback\n");
		return;
	}

	// Enable anchor point update events
	sdc_hci_cmd_vs_conn_anchor_point_update_event_report_enable_t enable_params = {
		.enable = true
	};
	err = hci_vs_sdc_conn_anchor_point_update_event_report_enable(&enable_params);
	if (err) {
		printk("Failed to enable connection anchor point update events\n");
		return;
	}

	timed_led_toggle_init();

	// Register additional ble callbacks for connect/disconnect
	bt_conn_cb_register(&conn_callbacks);

	scan_start();

	// Schedule event to toggle LED
	k_work_schedule(&timestamp_send_work, K_MSEC(LED_TOGGLE_PERIOD_MS));

	uart_console_command_loop();
}
```

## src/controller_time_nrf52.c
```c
/*
 * Copyright (c) 2024 Nordic Semiconductor ASA
 *
 * SPDX-License-Identifier: LicenseRef-Nordic-5-Clause
 */

/** This file implements controller time management for 52 Series devices
 *
 * As the controller clock is not directly accessible, the controller
 * time is obtained using a mirrored RTC peripheral.
 * To achieve microsecond accurate toggling, a timer peripheral is also used.
 */

#include <zephyr/kernel.h>
#include <zephyr/sys/barrier.h>
#include <mpsl_clock.h>
#include <nrfx_rtc.h>
#include <nrfx_timer.h>
#include <helpers/nrfx_gppi.h>
#include <nrfx_egu.h>
#include <hal/nrf_egu.h>
#include <soc.h>
#include "conn_time_sync.h"
#include "buzzer.h"
#include "uart_console.h"

static const nrfx_rtc_t app_rtc_instance = NRFX_RTC_INSTANCE(2);
static const nrfx_timer_t app_timer_instance = NRFX_TIMER_INSTANCE(1);

static const nrfx_egu_t egu_instance = NRFX_EGU_INSTANCE(0);

static volatile uint32_t num_rtc_overflows;

static uint32_t offset_ticks_and_controller_to_app_rtc;

static void rtc_isr_handler(nrfx_rtc_int_type_t int_type)
{
	if (int_type == NRFX_RTC_INT_OVERFLOW) {
		num_rtc_overflows++;
	}
}

static void egu_isr_handler(uint8_t event_idx, void * p_context)
{
	buzzer_set_arm_flag();
	nrfx_egu_int_disable(&egu_instance, 0x1);
}

static void unused_timer_isr_handler(nrf_timer_event_t event_type, void *ctx)
{
	ARG_UNUSED(event_type);
	ARG_UNUSED(ctx);
}

static int32_t rtc_diff_get(void)
{
	uint32_t controller_ticks = nrf_rtc_counter_get(NRF_RTC0);
	uint32_t app_ticks = nrf_rtc_counter_get(app_rtc_instance.p_reg);

	return controller_ticks - app_ticks;
}

static int rtc_config(void)
{
	int ret;

	const nrfx_rtc_config_t rtc_cfg = NRFX_RTC_DEFAULT_CONFIG;

	ret = nrfx_rtc_init(&app_rtc_instance, &rtc_cfg, rtc_isr_handler);
	if (ret != NRFX_SUCCESS) {
		printk("Failed initializing RTC (ret: %d)\n", ret - NRFX_ERROR_BASE_NUM);
		return -ENODEV;
	}

#ifndef BT_CTLR_SDC_BSIM_BUILD
	IRQ_CONNECT(NRFX_IRQ_NUMBER_GET(NRF_RTC_INST_GET(2)), IRQ_PRIO_LOWEST,
		    NRFX_RTC_INST_HANDLER_GET(2), NULL, 0);
#else
	IRQ_CONNECT(NRFX_IRQ_NUMBER_GET(NRF_RTC_INST_GET(2)), 0,
		    (void *)NRFX_RTC_INST_HANDLER_GET(2), NULL, 0);
#endif

	nrfx_rtc_overflow_enable(&app_rtc_instance, true);
	nrfx_rtc_tick_enable(&app_rtc_instance, false);
	nrfx_rtc_enable(&app_rtc_instance);

	/* To obtain the controller timestamp without modifying the state of RTC0,
	 * we find the offset between RTC0 and our mirrored RTC.
	 * We achieve this by reading out the counter value of both of them.
	 * When the diff between those two have been equal twice, we know the
	 * time difference in ticks.
	 */

	uint32_t sync_attempts = 10;

	while (sync_attempts > 0) {
		sync_attempts--;

		int32_t diff_measurement_1 = rtc_diff_get();

		/* We need to wait half an RTC tick to ensure we are not measuring
		 * the diff between the two RTCs at the point in time where their
		 * values are transitioning.
		 */
		k_busy_wait(15);

		int32_t diff_measurement_2 = rtc_diff_get();

		if (diff_measurement_1 == diff_measurement_2) {
			offset_ticks_and_controller_to_app_rtc = diff_measurement_1;
			return 0;
		}
	}

	printk("Controller time sync failure\n");
	offset_ticks_and_controller_to_app_rtc = 0;
	return -EINVAL;
}

static int timer_config(void)
{
	int ret;
	uint8_t ppi_chan_timer_clear_on_rtc_tick;
	const nrfx_timer_config_t timer_cfg = {
		.frequency = NRFX_MHZ_TO_HZ(1UL),
		.mode = NRF_TIMER_MODE_TIMER,
		.bit_width = NRF_TIMER_BIT_WIDTH_8,
		.interrupt_priority = NRFX_TIMER_DEFAULT_CONFIG_IRQ_PRIORITY,
		.p_context = NULL};

	ret = nrfx_timer_init(&app_timer_instance, &timer_cfg, unused_timer_isr_handler);
	if (ret != NRFX_SUCCESS) {
		printk("Failed initializing timer (ret: %d)\n", ret - NRFX_ERROR_BASE_NUM);
		return -ENODEV;
	}

	/* Clear the TIMER every RTC tick. */
	if (nrfx_gppi_channel_alloc(&ppi_chan_timer_clear_on_rtc_tick) != NRFX_SUCCESS) {
		printk("Failed allocating for clearing TIMER on RTC TICK\n");
		return -ENOMEM;
	}

	nrfx_gppi_channel_endpoints_setup(ppi_chan_timer_clear_on_rtc_tick,
					  nrfx_rtc_event_address_get(&app_rtc_instance,
								     NRF_RTC_EVENT_TICK),
					  nrfx_timer_task_address_get(&app_timer_instance,
								      NRF_TIMER_TASK_CLEAR));

	nrfx_gppi_channels_enable(BIT(ppi_chan_timer_clear_on_rtc_tick));

	nrfx_timer_enable(&app_timer_instance);

	return 0;
}

/** Configure the TIMER and RTC in such a way that microsecond accurate timing can be achieved.
 *
 * To get microsecond accurate toggling, we need to combine both the RTC and TIMER peripheral.
 * That is, both a RTC CC value and TIMER CC value needs to be set.
 * We should only trigger an EGU task when the TIMER CC value matches after the
 * RTC CC value matched.
 * This is achieved using a PPI group. The group is enabled when the RTC CC matches and disabled
 * again then the TIMER CC matches.
 */
int config_egu_trigger_on_rtc_and_timer_match(void)
{	
	int ret;
	uint8_t ppi_chan_on_rtc_match;
	uint8_t ppi_chan_on_timer_match;

	ret = nrfx_egu_init(&egu_instance, 0, egu_isr_handler, NULL);
	if (ret != NRFX_SUCCESS) {
		uart_console_printf("Failed initializing egu\n");
		return -ENODEV;
	}
	IRQ_CONNECT(NRFX_IRQ_NUMBER_GET(NRF_EGU_INST_GET(0)), 0,
            NRFX_EGU_INST_HANDLER_GET(0), NULL, 0);

	if (nrfx_gppi_channel_alloc(&ppi_chan_on_rtc_match) != NRFX_SUCCESS) {
		printk("Failed allocating for RTC match\n");
		return -ENOMEM;
	}

	if (nrfx_gppi_channel_alloc(&ppi_chan_on_timer_match) != NRFX_SUCCESS) {
		printk("Failed allocating for TIMER match\n");
		return -ENOMEM;
	}

	nrfx_gppi_group_clear(NRFX_GPPI_CHANNEL_GROUP0);
	nrfx_gppi_group_disable(NRFX_GPPI_CHANNEL_GROUP0);
	nrfx_gppi_channels_include_in_group(BIT(ppi_chan_on_timer_match),
					    NRFX_GPPI_CHANNEL_GROUP0);

	nrfx_gppi_channel_endpoints_setup(ppi_chan_on_rtc_match,
					  nrfx_rtc_event_address_get(&app_rtc_instance,
								     NRF_RTC_EVENT_COMPARE_0),
					  nrfx_gppi_task_address_get(NRFX_GPPI_TASK_CHG0_EN));

	nrfx_gppi_channel_endpoints_setup(ppi_chan_on_timer_match,
					  nrfx_timer_event_address_get(&app_timer_instance,
								       NRF_TIMER_EVENT_COMPARE0),
					  nrf_egu_task_address_get(NRF_EGU0,
								   NRF_EGU_TASK_TRIGGER0));
	nrfx_gppi_fork_endpoint_setup(ppi_chan_on_timer_match,
				      nrfx_gppi_task_address_get(NRFX_GPPI_TASK_CHG0_DIS));

	nrfx_gppi_channels_enable(BIT(ppi_chan_on_rtc_match));

	return 0;
}

int controller_time_init(void)
{
	int ret;

	ret = rtc_config();
	if (ret) {
		return ret;
	}

	ret = timer_config();
	if (ret) {
		return ret;
	}

	return config_egu_trigger_on_rtc_and_timer_match();
}

static uint64_t rtc_ticks_to_us(uint32_t rtc_ticks)
{
	const uint64_t rtc_ticks_in_femto_units = 30517578125UL;

	return (rtc_ticks * rtc_ticks_in_femto_units) / 1000000000UL;
}

static uint32_t us_to_rtc_ticks(uint32_t timestamp_us)
{
	const uint64_t rtc_ticks_in_femto_units = 30517578125UL;

	return ((uint64_t)(timestamp_us) * 1000000000UL) / rtc_ticks_in_femto_units;
}

uint64_t controller_time_us_get(void)
{
	const uint64_t rtc_overflow_time_us = 512000000UL;

	/* On the 52 series the RTC has to task to capture the current RTC value.
	 * Therefore we cannot capture the TIMER and RTC value simultaneously.
	 * Therefore we only use the RTC to read out the current time here.
	 * This will result in an error of maximum one RTC tick.
	 */

	uint32_t captured_rtc_overflows;
	uint32_t captured_rtc_ticks;

	while (true) {
		captured_rtc_overflows = num_rtc_overflows;

		/* Read out RTC ticks after reading number of overflows. */
		barrier_isync_fence_full();

		captured_rtc_ticks = nrf_rtc_counter_get(app_rtc_instance.p_reg);

		/* Read out number of overflows after reading number of RTC ticks  */
		barrier_isync_fence_full();

		if (captured_rtc_overflows == num_rtc_overflows) {
			/* There were no new overflows after reading ticks.
			 * That is, we can use the captured value.
			 */
			break;
		}
	}

	return rtc_ticks_to_us(captured_rtc_ticks) +
	       (captured_rtc_overflows * rtc_overflow_time_us) +
	       rtc_ticks_to_us(offset_ticks_and_controller_to_app_rtc);
}

void controller_time_trigger_set(uint64_t timestamp_us)
{
	uint64_t timestamp_without_rtc_offset =
		timestamp_us - rtc_ticks_to_us(offset_ticks_and_controller_to_app_rtc);

	uint32_t num_overflows = timestamp_without_rtc_offset / 512000000UL;
	uint64_t overflow_time_us = num_overflows * 512000000UL;

	uint32_t rtc_remainder_time_us = timestamp_without_rtc_offset - overflow_time_us;
	uint32_t rtc_val = us_to_rtc_ticks(rtc_remainder_time_us);
	uint8_t timer_val =	timestamp_without_rtc_offset - rtc_ticks_to_us(rtc_val);

	/* Ensure the timer value lies between 1 and 30 so that it will
	 * always be between two RTC ticks.
	 */
	timer_val = MAX(timer_val, 1);
	timer_val = MIN(timer_val, 30);

	if (nrfx_rtc_cc_set(&app_rtc_instance, 0, rtc_val, false) != NRFX_SUCCESS) {
		printk("Failed setting trigger\n");
	}

	nrfx_timer_compare(&app_timer_instance, 0, timer_val, false);

	nrfx_egu_int_enable(&egu_instance, 0x1);
}

uint32_t controller_time_trigger_event_addr_get(void)
{
	return nrf_egu_event_address_get(NRF_EGU0, NRF_EGU_EVENT_TRIGGERED0);
}

SYS_INIT(controller_time_init, POST_KERNEL, CONFIG_KERNEL_INIT_PRIORITY_DEFAULT);
```

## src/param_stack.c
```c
#include <zephyr/kernel.h>
#include <zephyr/init.h>
#include "zephyr/bluetooth/gatt.h"

#define MAX_ITEMS 50

static struct bt_gatt_write_params write_params[MAX_ITEMS];
static struct bt_gatt_read_params read_params[MAX_ITEMS];

K_STACK_DEFINE(write_stack, MAX_ITEMS);
K_STACK_DEFINE(read_stack, MAX_ITEMS);

static int param_stack_init(void)
{
    // Push to stacks
    int i;
    for(i = 0; i < MAX_ITEMS; i++){
        k_stack_push(&write_stack, (stack_data_t)&write_params[i]);
        k_stack_push(&read_stack, (stack_data_t)&read_params[i]);
    }
    return 0;
}

int param_stack_get_write(struct bt_gatt_write_params **data)
{
    return k_stack_pop(&write_stack, (stack_data_t*)data, K_NO_WAIT);
}

int param_stack_get_read(struct bt_gatt_read_params **data)
{
    return k_stack_pop(&read_stack,(stack_data_t*)data, K_NO_WAIT);  
}

int param_stack_free_write(struct bt_gatt_write_params *data)
{
    return k_stack_push(&write_stack, (stack_data_t)data);
}

int param_stack_free_read(struct bt_gatt_read_params *data)
{
    return k_stack_push(&read_stack, (stack_data_t)data);
}

SYS_INIT(param_stack_init, APPLICATION, CONFIG_KERNEL_INIT_PRIORITY_DEFAULT);
```
